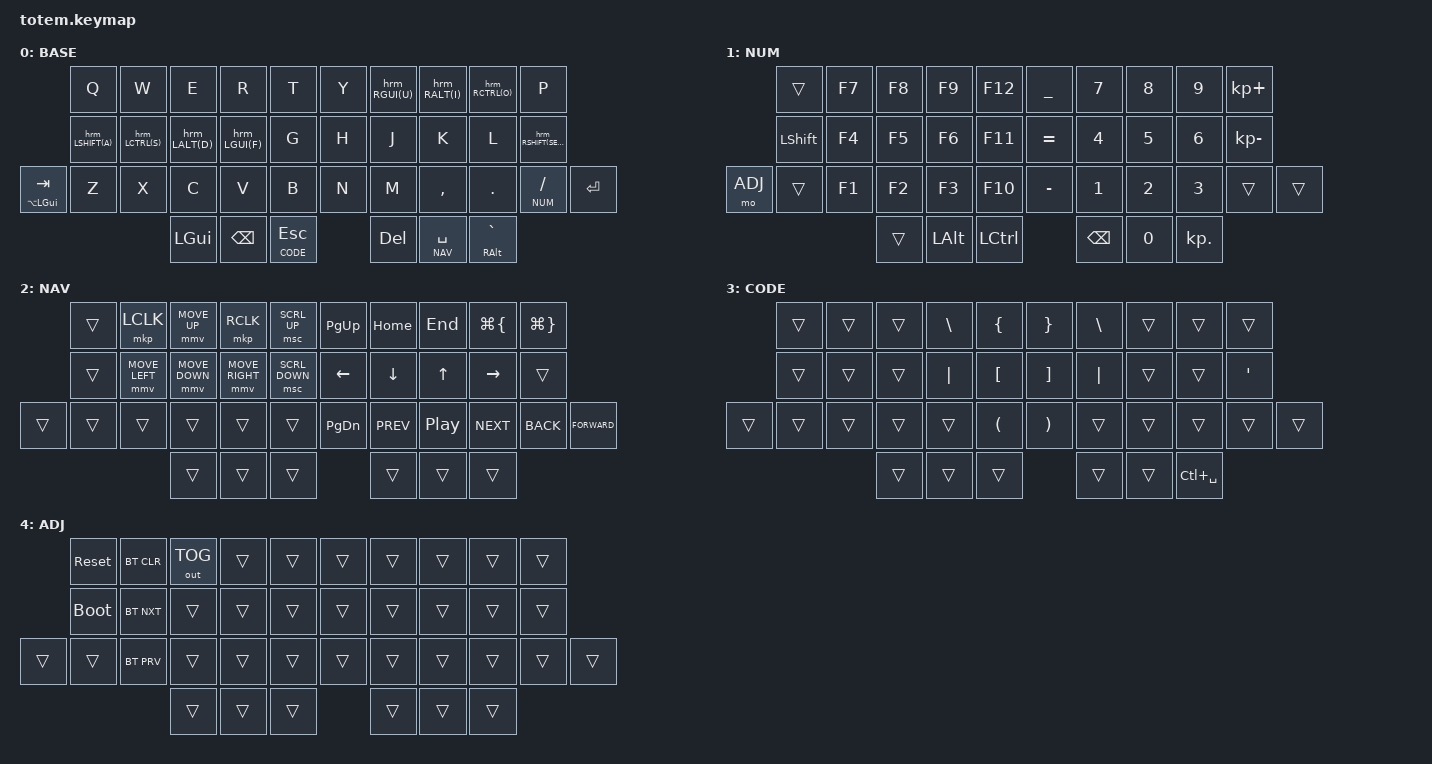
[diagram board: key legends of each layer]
//
//                                                        ▀▀▀▀▀     ▀▀▀▀▀          ▀▀█▀▀
//                                                        ▄▀▀▀▄  ▄  ▄▀▀▀▄  ▄  ▄▀▀▀▄  █  ▄▀▀▀▄
//                                                        █   █  █  █   █  █  █   █  █  █   █
//                                                         ▀▀▀   █   ▀▀▀   █   ▀▀▀   ▀   ▀▀▀
//                                                               █      ▄▄▄█▄▄▄    █   █  
//                                                               ▀      █  █  █     █▄█
//                                                             ▀▀▀▀▀    █  █  █      ▀
//                                                                      ▀  ▀  ▀          dluksza
//
// ▄▄▄▄▄▄▄▄▄▄▄▄▄▄▄▄▄▄▄▄▄▄▄▄▄▄▄▄▄▄▄▄▄▄▄▄▄▄▄▄▄▄▄▄▄▄▄▄▄▄▄▄▄▄▄▄▄▄▄▄▄▄▄▄▄▄▄▄▄▄▄▄▄▄▄▄▄▄▄▄▄▄▄▄▄▄▄▄▄▄▄▄▄▄▄▄▄▄▄▄▄▄▄▄▄▄▄▄▄▄▄▄▄▄▄▄▄▄▄▄▄▄▄▄▄▄▄▄▄▄▄▄▄▄▄▄▄▄▄▄▄▄▄▄▄▄▄▄▄
       

#include <behaviors.dtsi>
#include <dt-bindings/zmk/keys.h>
#include <dt-bindings/zmk/bt.h>
#include <dt-bindings/zmk/outputs.h>
#include <dt-bindings/zmk/pointing.h>

#define BASE 0
#define NUM  1
#define NAV  2
#define CODE 3
#define ADJ  4

#define KEYS_L 4 3 2 1 0 14 13 12 11 10 25 24 23 22 21 20   // left-hand keys
#define KEYS_R 5 6 7 8 9 15 16 17 18 19 26 27 28 29 30 31   // right-hand keys
#define THUMBS 32 33 34 35 36 37                            // thumb keys

/** -- Home Row Mods -- **/
#define TAPPING_TERM_MS 220
#define REQUIRE_PRIOR_IDLE_MS 160
#define QUICK_TAP_MS 310

#define hrm_LSHIFT(key) &hrmL_pinky  LSHIFT key
#define hrm_LCTRL(key)  &hrmL_ring   LCTRL key
#define hrm_LALT(key)   &hrmL_middle LALT key
#define hrm_LGUI(key)   &hrmL_index  LGUI key

#define hrm_RSHIFT(key) &hrmR_pinky  RSHIFT key
#define hrm_RCTRL(key)  &hrmR_ring   RCTRL key
#define hrm_RALT(key)   &hrmR_middle RALT key
#define hrm_RGUI(key)   &hrmR_index  RGUI key

/ {
     behaviours {
        /** -- Home Row Mods - Left Hand -- **/
        hrmL_pinky: home_row_mod_left_pinky {
            compatible = "zmk,behavior-hold-tap";
            flavor = "tap-preferred";
            hold-trigger-key-positions = <KEYS_R THUMBS>;
            tapping-term-ms = <200>;
            quick-tap-ms = <175>;
            #binding-cells = <2>;
            bindings = <&kp>, <&kp>;
        };

        hrmL_ring: home_row_mod_left_ring {
            compatible = "zmk,behavior-hold-tap";
            flavor = "tap-preferred";
            hold-trigger-key-positions = <KEYS_R THUMBS>;
            hold-trigger-on-release;
            tapping-term-ms = <260>;
            quick-tap-ms = <300>;
            require-prior-idle-ms = <REQUIRE_PRIOR_IDLE_MS>;
            #binding-cells = <2>;
            bindings = <&kp>, <&kp>;
        };

        hrmL_middle: home_row_mod_left_middle {
            compatible = "zmk,behavior-hold-tap";
            flavor = "tap-preferred";
            hold-trigger-key-positions = <KEYS_R THUMBS>;
            hold-trigger-on-release;
            tapping-term-ms = <TAPPING_TERM_MS>;
            quick-tap-ms = <225>;
            require-prior-idle-ms = <REQUIRE_PRIOR_IDLE_MS>;
            #binding-cells = <2>;
            bindings = <&kp>, <&kp>;
        };

        hrmL_index: home_row_mod_left_index {
            compatible = "zmk,behavior-hold-tap";
            flavor = "tap-preferred";
            hold-trigger-key-positions = <KEYS_R THUMBS>;
            hold-trigger-on-release;
            tapping-term-ms = <TAPPING_TERM_MS>;
            quick-tap-ms = <QUICK_TAP_MS>;
            require-prior-idle-ms = <REQUIRE_PRIOR_IDLE_MS>;
            #binding-cells = <2>;
            bindings = <&kp>, <&kp>;
        };

        /** -- Home Row Mods - Right Hand -- **/
        hrmR_index: home_row_mod_right_index {
            compatible = "zmk,behavior-hold-tap";
            flavor = "tap-preferred";
            hold-trigger-key-positions = <KEYS_L THUMBS>;
            hold-trigger-on-release;
            tapping-term-ms = <TAPPING_TERM_MS>;
            quick-tap-ms = <QUICK_TAP_MS>;
            require-prior-idle-ms = <REQUIRE_PRIOR_IDLE_MS>;
            #binding-cells = <2>;
            bindings = <&kp>, <&kp>;
        };

        hrmR_middle: home_row_mod_right_middle {
            compatible = "zmk,behavior-hold-tap";
            flavor = "tap-preferred";
            hold-trigger-key-positions = <KEYS_L THUMBS>;
            hold-trigger-on-release;
            tapping-term-ms = <240>;
            quick-tap-ms = <270>;
            require-prior-idle-ms = <REQUIRE_PRIOR_IDLE_MS>;
            #binding-cells = <2>;
            bindings = <&kp>, <&kp>;
        };

        hrmR_ring: home_row_mod_right_ring {
            compatible = "zmk,behavior-hold-tap";
            flavor = "balanced";
            hold-trigger-key-positions = <KEYS_L THUMBS>;
            hold-trigger-on-release;
            tapping-term-ms = <280>;
            quick-tap-ms = <300>;
            require-prior-idle-ms = <180>;
            #binding-cells = <2>;
            bindings = <&kp>, <&kp>;
        };

        hrmR_pinky: home_row_mod_right_pinky {
            compatible = "zmk,behavior-hold-tap";
            flavor = "tap-preferred";
            hold-trigger-key-positions = <KEYS_L THUMBS>;
            tapping-term-ms = <200>;
            quick-tap-ms = <175>;
            #binding-cells = <2>;
            bindings = <&kp>, <&kp>;
        };

        fast_lt: fast_layer_tap {
            compatible = "zmk,behavior-hold-tap";
            #binding-cells = <2>;
            flavor = "hold-preferred";
            tapping-term-ms = <150>;
            bindings = <&mo>, <&kp>;
        };
     };

     keymap {
                compatible = "zmk,keymap";
// ▄▄▄▄▄▄▄▄▄▄▄▄▄▄▄▄▄▄▄▄▄▄▄▄▄▄▄▄▄▄▄▄▄▄▄▄▄▄▄▄▄▄▄▄▄▄▄▄▄▄▄▄▄▄▄▄▄▄▄▄▄▄▄▄▄▄▄▄▄▄▄▄▄▄▄▄▄▄▄▄▄▄▄▄▄▄▄▄▄▄▄▄▄▄▄▄▄▄▄▄▄▄▄▄▄▄▄▄▄▄▄▄▄▄▄▄▄▄▄▄▄▄▄▄▄▄▄▄▄▄▄▄▄▄▄▄▄▄▄▄▄▄▄▄▄▄▄▄▄

                base_layer {
// ┏━━━━━━━━━━━━━━━━━━━━━━━━━━━━━━━━━━━━━━━┓
display-name= "BASE"                              ;
// ┗━━━━━━━━━━━━━━━━━━━━━━━━━━━━━━━━━━━━━━━┛
//             ┏━━━━━━━━━━━┳━━━━━━━━━━━┳━━━━━━━━━━━┳━━━━━━━━━━━┳━━━━━━━━━━━┓   ┏━━━━━━━━━━━┳━━━━━━━━━━━┳━━━━━━━━━━━┳━━━━━━━━━━━┳━━━━━━━━━━━┓
//             ┃     Q     ┃     W     ┃     E     ┃     R     ┃     T     ┃   ┃     Y     ┃    ⌘/U    ┃    ⌥/I    ┃    ^/O    ┃     P     ┃
//             ┣━━━━━━━━━━━╋━━━━━━━━━━━╋━━━━━━━━━━━╋━━━━━━━━━━━╋━━━━━━━━━━━┫   ┣━━━━━━━━━━━╋━━━━━━━━━━━╋━━━━━━━━━━━╋━━━━━━━━━━━╋━━━━━━━━━━━┫
//             ┃    ⇧/A    ┃    ^/S    ┃    ⌥/D    ┃    ⌘/F    ┃     G     ┃   ┃     H     ┃     J     ┃     K     ┃     L     ┃    ⇧/;    ┃
// ┏━━━━━━━━━━━╋━━━━━━━━━━━╋━━━━━━━━━━━╋━━━━━━━━━━━╋━━━━━━━━━━━╋━━━━━━━━━━━┫   ┣━━━━━━━━━━━╋━━━━━━━━━━━╋━━━━━━━━━━━╋━━━━━━━━━━━╋━━━━━━━━━━━╋━━━━━━━━━━━┓
// ┃ meh TAB   ┃     Z     ┃     X     ┃     C     ┃     V     ┃     B     ┃   ┃     N     ┃     M     ┃     ,     ┃     .     ┃   num /   ┃   ENTER   ┃
// ┗━━━━━━━━━━━┻━━━━━━━━━━━┻━━━━━━━━━━━╋━━━━━━━━━━━╋━━━━━━━━━━━╋━━━━━━━━━━━┫   ┣━━━━━━━━━━━╋━━━━━━━━━━━╋━━━━━━━━━━━╋━━━━━━━━━━━┻━━━━━━━━━━━┻━━━━━━━━━━━┛
//                                     ┃     ⌘     ┃   BSPC    ┃ code ESC  ┃   ┃    DEL    ┃ nav SPC   ┃    ⌥/`    ┃
//                                     ┗━━━━━━━━━━━┻━━━━━━━━━━━┻━━━━━━━━━━━┛   ┗━━━━━━━━━━━┻━━━━━━━━━━━┻━━━━━━━━━━━┛
 bindings = <
// ╷               ╷             ╷            ╷           ╷           ╷            ╷  ╷       ╷             ╷              ╷            ╷                ╷       ╷

                    &kp Q         &kp W        &kp E       &kp R       &kp T           &kp Y   hrm_RGUI(U)   hrm_RALT(I)    hrm_RCTRL(O) &kp P
                    hrm_LSHIFT(A) hrm_LCTRL(S) hrm_LALT(D) hrm_LGUI(F) &kp G           &kp H   &kp J         &kp K          &kp L        hrm_RSHIFT(SEMI)
   &mt LA(LGUI) TAB &kp Z         &kp X        &kp C       &kp V       &kp B           &kp N   &kp M         &kp COMMA      &kp DOT      &lt NUM FSLH     &kp RET
                                               &kp LGUI    &kp BSPC    &fast_lt CODE ESC    &kp DEL &lt NAV SPACE &mt RALT GRAVE
            >;
                };

// ▄▄▄▄▄▄▄▄▄▄▄▄▄▄▄▄▄▄▄▄▄▄▄▄▄▄▄▄▄▄▄▄▄▄▄▄▄▄▄▄▄▄▄▄▄▄▄▄▄▄▄▄▄▄▄▄▄▄▄▄▄▄▄▄▄▄▄▄▄▄▄▄▄▄▄▄▄▄▄▄▄▄▄▄▄▄▄▄▄▄▄▄▄▄▄▄▄▄▄▄▄▄▄▄▄▄▄▄▄▄▄▄▄▄▄▄▄▄▄▄▄▄▄▄▄▄▄▄▄▄▄▄▄▄▄▄▄▄▄▄▄▄▄▄▄▄▄▄▄

                num_layer {
// ┏━━━━━━━━━━━━━━━━━━━━━━━━━━━━━━━━━━━━━━━┓
display-name= "NUM"                               ;
// ┗━━━━━━━━━━━━━━━━━━━━━━━━━━━━━━━━━━━━━━━┛
//             ┏━━━━━━━━━━━┳━━━━━━━━━━━┳━━━━━━━━━━━┳━━━━━━━━━━━┳━━━━━━━━━━━┓   ┏━━━━━━━━━━━┳━━━━━━━━━━━┳━━━━━━━━━━━┳━━━━━━━━━━━┳━━━━━━━━━━━┓
//             ┃           ┃    F7     ┃    F8     ┃    F9     ┃    F12    ┃   ┃     _     ┃     7     ┃     8     ┃     9     ┃     +     ┃
//             ┣━━━━━━━━━━━╋━━━━━━━━━━━╋━━━━━━━━━━━╋━━━━━━━━━━━╋━━━━━━━━━━━┫   ┣━━━━━━━━━━━╋━━━━━━━━━━━╋━━━━━━━━━━━╋━━━━━━━━━━━╋━━━━━━━━━━━┫
//             ┃   SHIFT   ┃    F4     ┃    F5     ┃    F6     ┃    F11    ┃   ┃     =     ┃     4     ┃     5     ┃     6     ┃     -     ┃
// ┏━━━━━━━━━━━╋━━━━━━━━━━━╋━━━━━━━━━━━╋━━━━━━━━━━━╋━━━━━━━━━━━╋━━━━━━━━━━━┫   ┣━━━━━━━━━━━╋━━━━━━━━━━━╋━━━━━━━━━━━╋━━━━━━━━━━━╋━━━━━━━━━━━╋━━━━━━━━━━━┓
// ┃    ADJ    ┃           ┃    F1     ┃    F2     ┃    F3     ┃    F10    ┃   ┃     -     ┃     1     ┃     2     ┃     3     ┃     ⇓     ┃           ┃
// ┗━━━━━━━━━━━┻━━━━━━━━━━━┻━━━━━━━━━━━╋━━━━━━━━━━━╋━━━━━━━━━━━╋━━━━━━━━━━━┫   ┣━━━━━━━━━━━╋━━━━━━━━━━━╋━━━━━━━━━━━╋━━━━━━━━━━━┻━━━━━━━━━━━┻━━━━━━━━━━━┛
//                                     ┃           ┃     ⌥     ┃     ^     ┃   ┃   BSPC    ┃     0     ┃     .     ┃
//                                     ┗━━━━━━━━━━━┻━━━━━━━━━━━┻━━━━━━━━━━━┛   ┗━━━━━━━━━━━┻━━━━━━━━━━━┻━━━━━━━━━━━┛
 bindings = <
// ╷           ╷           ╷           ╷           ╷           ╷           ╷   ╷           ╷           ╷           ╷           ╷           ╷           ╷

               &trans      &kp F7      &kp F8      &kp F9      &kp F12         &kp UNDER   &kp N7      &kp N8      &kp N9      &kp KP_PLUS
               &kp LSHFT   &kp F4      &kp F5      &kp F6      &kp F11         &kp EQUAL   &kp N4      &kp N5      &kp N6      &kp KP_MINUS
   &mo ADJ     &trans      &kp F1      &kp F2      &kp F3      &kp F10         &kp MINUS   &kp N1      &kp N2      &kp N3      &trans      &trans
                                       &trans      &kp LALT    &kp LCTRL       &kp BSPC    &kp N0      &kp KP_DOT
            >;
                };

// ▄▄▄▄▄▄▄▄▄▄▄▄▄▄▄▄▄▄▄▄▄▄▄▄▄▄▄▄▄▄▄▄▄▄▄▄▄▄▄▄▄▄▄▄▄▄▄▄▄▄▄▄▄▄▄▄▄▄▄▄▄▄▄▄▄▄▄▄▄▄▄▄▄▄▄▄▄▄▄▄▄▄▄▄▄▄▄▄▄▄▄▄▄▄▄▄▄▄▄▄▄▄▄▄▄▄▄▄▄▄▄▄▄▄▄▄▄▄▄▄▄▄▄▄▄▄▄▄▄▄▄▄▄▄▄▄▄▄▄▄▄▄▄▄▄▄▄▄▄


                nav_layer {
// ┏━━━━━━━━━━━━━━━━━━━━━━━━━━━━━━━━━━━━━━━┓
display-name= "NAV"                               ;
// ┗━━━━━━━━━━━━━━━━━━━━━━━━━━━━━━━━━━━━━━━┛
//             ┏━━━━━━━━━━━┳━━━━━━━━━━━┳━━━━━━━━━━━┳━━━━━━━━━━━┳━━━━━━━━━━━┓   ┏━━━━━━━━━━━┳━━━━━━━━━━━┳━━━━━━━━━━━┳━━━━━━━━━━━┳━━━━━━━━━━━┓
//             ┃           ┃    LMB    ┃     UP    ┃    RMB    ┃  SC UP    ┃   ┃   PgUp    ┃   HOME    ┃    End    ┃ Next Tab  ┃ Prev Tab  ┃
//             ┣━━━━━━━━━━━╋━━━━━━━━━━━╋━━━━━━━━━━━╋━━━━━━━━━━━╋━━━━━━━━━━━┫   ┣━━━━━━━━━━━╋━━━━━━━━━━━╋━━━━━━━━━━━╋━━━━━━━━━━━╋━━━━━━━━━━━┫
//             ┃           ┃    LEFT   ┃    DOWN   ┃   RIGHT   ┃  SC DOWN  ┃   ┃     ⬅     ┃     ⬇     ┃     ⬆     ┃     →     ┃           ┃
// ┏━━━━━━━━━━━╋━━━━━━━━━━━╋━━━━━━━━━━━╋━━━━━━━━━━━╋━━━━━━━━━━━╋━━━━━━━━━━━┫   ┣━━━━━━━━━━━╋━━━━━━━━━━━╋━━━━━━━━━━━╋━━━━━━━━━━━╋━━━━━━━━━━━╋━━━━━━━━━━━┓
// ┃           ┃           ┃           ┃           ┃           ┃           ┃   ┃   PgDn    ┃  M Prev   ┃  M Play   ┃  M Next   ┃    Back   ┃  Forward  ┃
// ┗━━━━━━━━━━━┻━━━━━━━━━━━┻━━━━━━━━━━━╋━━━━━━━━━━━╋━━━━━━━━━━━╋━━━━━━━━━━━┫   ┣━━━━━━━━━━━╋━━━━━━━━━━━╋━━━━━━━━━━━╋━━━━━━━━━━━┻━━━━━━━━━━━┻━━━━━━━━━━━┛
//                                     ┃           ┃           ┃           ┃   ┃           ┃     ⇓     ┃           ┃
//                                     ┗━━━━━━━━━━━┻━━━━━━━━━━━┻━━━━━━━━━━━┛   ┗━━━━━━━━━━━┻━━━━━━━━━━━┻━━━━━━━━━━━┛
 bindings = <
// ╷           ╷           ╷           ╷           ╷           ╷           ╷   ╷             ╷            ╷           ╷           ╷           ╷           ╷

               &trans      &mkp LCLK      &mmv MOVE_UP   &mkp RCLK       &msc SCRL_UP    &kp PAGE_UP   &kp HOME     &kp END     &kp LG(LBRC) &kp LG(RBRC)
               &trans      &mmv MOVE_LEFT &mmv MOVE_DOWN &mmv MOVE_RIGHT &msc SCRL_DOWN  &kp LEFT      &kp DOWN     &kp UP      &kp RIGHT    &trans
   &trans      &trans      &trans         &trans         &trans          &trans          &kp PAGE_DOWN &kp C_PREV   &kp C_PP    &kp C_NEXT   &kp K_BACK &kp K_FORWARD
                                          &trans         &trans          &trans          &trans        &trans       &trans
            >;
                };

// ▄▄▄▄▄▄▄▄▄▄▄▄▄▄▄▄▄▄▄▄▄▄▄▄▄▄▄▄▄▄▄▄▄▄▄▄▄▄▄▄▄▄▄▄▄▄▄▄▄▄▄▄▄▄▄▄▄▄▄▄▄▄▄▄▄▄▄▄▄▄▄▄▄▄▄▄▄▄▄▄▄▄▄▄▄▄▄▄▄▄▄▄▄▄▄▄▄▄▄▄▄▄▄▄▄▄▄▄▄▄▄▄▄▄▄▄▄▄▄▄▄▄▄▄▄▄▄▄▄▄▄▄▄▄▄▄▄▄▄▄▄▄▄▄▄▄▄▄▄


                code_layer {
// ┏━━━━━━━━━━━━━━━━━━━━━━━━━━━━━━━━━━━━━━━┓
display-name= "CODE"                              ;
// ┗━━━━━━━━━━━━━━━━━━━━━━━━━━━━━━━━━━━━━━━┛
//             ┏━━━━━━━━━━━┳━━━━━━━━━━━┳━━━━━━━━━━━┳━━━━━━━━━━━┳━━━━━━━━━━━┓   ┏━━━━━━━━━━━┳━━━━━━━━━━━┳━━━━━━━━━━━┳━━━━━━━━━━━┳━━━━━━━━━━━┓
//             ┃           ┃           ┃           ┃     \     ┃     {     ┃   ┃     }     ┃     \     ┃           ┃           ┃           ┃
//             ┣━━━━━━━━━━━╋━━━━━━━━━━━╋━━━━━━━━━━━╋━━━━━━━━━━━╋━━━━━━━━━━━┫   ┣━━━━━━━━━━━╋━━━━━━━━━━━╋━━━━━━━━━━━╋━━━━━━━━━━━╋━━━━━━━━━━━┫
//             ┃           ┃           ┃           ┃     |     ┃     [     ┃   ┃     ]     ┃     |     ┃           ┃           ┃     '     ┃
// ┏━━━━━━━━━━━╋━━━━━━━━━━━╋━━━━━━━━━━━╋━━━━━━━━━━━╋━━━━━━━━━━━╋━━━━━━━━━━━┫   ┣━━━━━━━━━━━╋━━━━━━━━━━━╋━━━━━━━━━━━╋━━━━━━━━━━━╋━━━━━━━━━━━╋━━━━━━━━━━━┓
// ┃           ┃           ┃           ┃           ┃           ┃     (     ┃   ┃     )     ┃           ┃           ┃           ┃           ┃           ┃
// ┗━━━━━━━━━━━┻━━━━━━━━━━━┻━━━━━━━━━━━╋━━━━━━━━━━━╋━━━━━━━━━━━╋━━━━━━━━━━━┫   ┣━━━━━━━━━━━╋━━━━━━━━━━━╋━━━━━━━━━━━╋━━━━━━━━━━━┻━━━━━━━━━━━┻━━━━━━━━━━━┛
//                                     ┃           ┃           ┃     ⇓     ┃   ┃           ┃           ┃ ctrl+spc  ┃
//                                     ┗━━━━━━━━━━━┻━━━━━━━━━━━┻━━━━━━━━━━━┛   ┗━━━━━━━━━━━┻━━━━━━━━━━━┻━━━━━━━━━━━┛
 bindings = <
// ╷           ╷           ╷           ╷           ╷           ╷           ╷   ╷             ╷            ╷           ╷           ╷           ╷           ╷

               &trans      &trans      &trans      &kp BSLH    &kp LBRC        &kp RBRC      &kp BSLH     &trans      &trans      &trans
               &trans      &trans      &trans      &kp PIPE    &kp LBKT        &kp RBKT      &kp PIPE     &trans      &trans      &kp SQT
   &trans      &trans      &trans      &trans      &trans      &kp LPAR        &kp RPAR      &trans       &trans      &trans      &trans      &trans
                                       &trans      &trans      &trans          &trans        &trans       &kp LC(SPACE)
            >;
                };


// ▄▄▄▄▄▄▄▄▄▄▄▄▄▄▄▄▄▄▄▄▄▄▄▄▄▄▄▄▄▄▄▄▄▄▄▄▄▄▄▄▄▄▄▄▄▄▄▄▄▄▄▄▄▄▄▄▄▄▄▄▄▄▄▄▄▄▄▄▄▄▄▄▄▄▄▄▄▄▄▄▄▄▄▄▄▄▄▄▄▄▄▄▄▄▄▄▄▄▄▄▄▄▄▄▄▄▄▄▄▄▄▄▄▄▄▄▄▄▄▄▄▄▄▄▄▄▄▄▄▄▄▄▄▄▄▄▄▄▄▄▄▄▄▄▄▄▄▄


                adjust_layer {
// ┏━━━━━━━━━━━━━━━━━━━━━━━━━━━━━━━━━━━━━━━┓
display-name= "ADJ"                               ;
// ┗━━━━━━━━━━━━━━━━━━━━━━━━━━━━━━━━━━━━━━━┛
//             ┏━━━━━━━━━━━┳━━━━━━━━━━━┳━━━━━━━━━━━┳━━━━━━━━━━━┳━━━━━━━━━━━┓   ┏━━━━━━━━━━━┳━━━━━━━━━━━┳━━━━━━━━━━━┳━━━━━━━━━━━┳━━━━━━━━━━━┓
//             ┃   RESET   ┃ BT CLEAR  ┃  OUT TOG  ┃           ┃           ┃   ┃           ┃           ┃           ┃           ┃           ┃
//             ┣━━━━━━━━━━━╋━━━━━━━━━━━╋━━━━━━━━━━━╋━━━━━━━━━━━╋━━━━━━━━━━━┫   ┣━━━━━━━━━━━╋━━━━━━━━━━━╋━━━━━━━━━━━╋━━━━━━━━━━━╋━━━━━━━━━━━┫
//             ┃ BOOTLOAD  ┃ BT NEXT   ┃           ┃           ┃           ┃   ┃           ┃           ┃           ┃           ┃           ┃
// ┏━━━━━━━━━━━╋━━━━━━━━━━━╋━━━━━━━━━━━╋━━━━━━━━━━━╋━━━━━━━━━━━╋━━━━━━━━━━━┫   ┣━━━━━━━━━━━╋━━━━━━━━━━━╋━━━━━━━━━━━╋━━━━━━━━━━━╋━━━━━━━━━━━╋━━━━━━━━━━━┓
// ┃           ┃           ┃ BT PREV   ┃           ┃           ┃           ┃   ┃           ┃           ┃           ┃           ┃           ┃           ┃
// ┗━━━━━━━━━━━┻━━━━━━━━━━━┻━━━━━━━━━━━╋━━━━━━━━━━━╋━━━━━━━━━━━╋━━━━━━━━━━━┫   ┣━━━━━━━━━━━╋━━━━━━━━━━━╋━━━━━━━━━━━╋━━━━━━━━━━━┻━━━━━━━━━━━┻━━━━━━━━━━━┛
//                                     ┃           ┃           ┃           ┃   ┃           ┃           ┃           ┃
//                                     ┗━━━━━━━━━━━┻━━━━━━━━━━━┻━━━━━━━━━━━┛   ┗━━━━━━━━━━━┻━━━━━━━━━━━┻━━━━━━━━━━━┛
 bindings = <
// ╷           ╷           ╷           ╷            ╷           ╷           ╷   ╷           ╷           ╷           ╷           ╷           ╷           ╷

               &sys_reset  &bt BT_CLR  &out OUT_TOG &trans      &trans          &trans      &trans      &trans      &trans      &trans
               &bootloader &bt BT_NXT  &trans       &trans      &trans          &trans      &trans      &trans      &trans      &trans
   &trans      &trans      &bt BT_PRV  &trans       &trans      &trans          &trans      &trans      &trans      &trans      &trans      &trans
                                       &trans       &trans      &trans          &trans      &trans      &trans
            >;
                };

// ▄▄▄▄▄▄▄▄▄▄▄▄▄▄▄▄▄▄▄▄▄▄▄▄▄▄▄▄▄▄▄▄▄▄▄▄▄▄▄▄▄▄▄▄▄▄▄▄▄▄▄▄▄▄▄▄▄▄▄▄▄▄▄▄▄▄▄▄▄▄▄▄▄▄▄▄▄▄▄▄▄▄▄▄▄▄▄▄▄▄▄▄▄▄▄▄▄▄▄▄▄▄▄▄▄▄▄▄▄▄▄▄▄▄▄▄▄▄▄▄▄▄▄▄▄▄▄▄▄▄▄▄▄▄▄▄▄▄▄▄▄▄▄▄▄▄▄▄▄

        };
};
